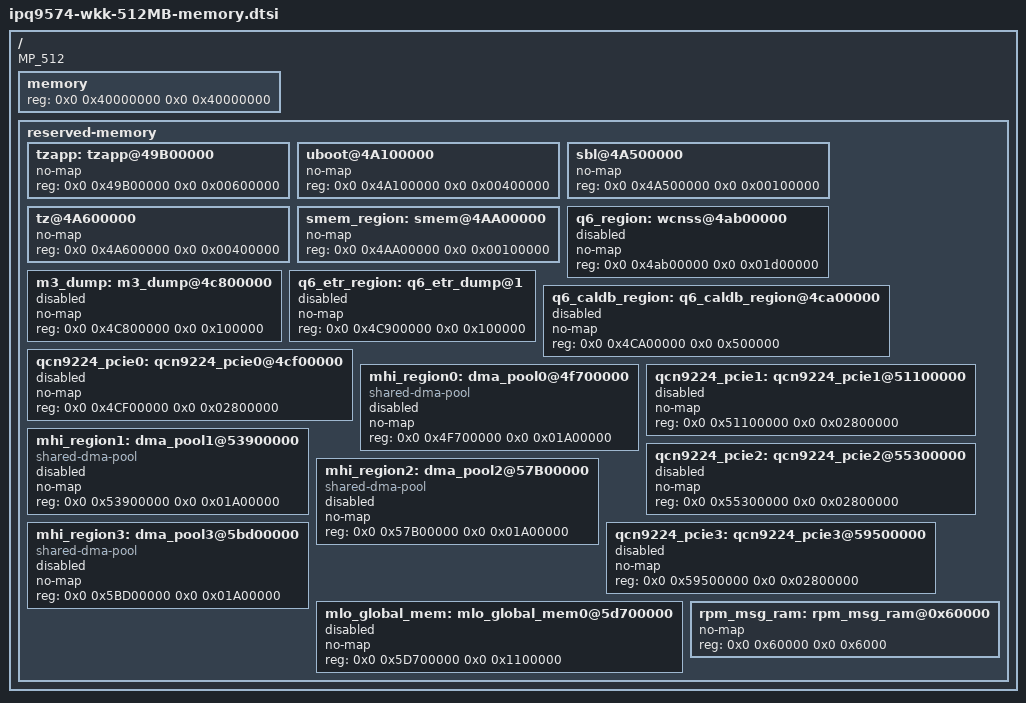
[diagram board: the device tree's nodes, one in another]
// SPDX-License-Identifier: (GPL-2.0+ OR BSD-3-Clause)
/*
 * IPQ9574 Memory device tree source
 *
 * Copyright (c) 2021 The Linux Foundation. All rights reserved.
 * Copyright (c) 2021-2022 Qualcomm Innovation Center, Inc. All rights reserved.
 */

/ {
	MP_512;

	/*		512M Profile for Waikiki
	 * +========+==============+=========================+
	 * |        |              |                         |
	 * | Region | Start Offset |          Size           |
	 * |        |              |                         |
	 * +--------+--------------+-------------------------+
	 * |        |              |                         |
	 * |        |              |                         |
	 * |        |              |                         |
	 * |        |              |                         |
	 * | Linux  |  0x42000000  |         123MB           |
	 * |        |              |                         |
	 * |        |              |                         |
	 * |        |              |                         |
	 * +--------+--------------+-------------------------+
	 * |        |              |                         |
	 * |        |              |                         |
	 * | TZ App |  0x49B00000  |           6MB           |
	 * |        |              |                         |
	 * |        |              |                         |
	 * +--------+--------------+-------------------------+
	 * |        |              |                         |
	 * | uboot  |  0x4A100000  |           4MB           |
	 * |        |              |                         |
	 * +--------+--------------+-------------------------+
	 * |  SBL   |  0x4A500000  |           1MB           |
	 * +--------+--------------+-------------------------+
	 * |        |              |                         |
	 * | TZ+HYP |  0x4A600000  |           4MB           |
	 * |        |              |                         |
	 * +--------+--------------+-------------------------+
	 * |  smem  |  0x4AA00000  |           1MB           |
	 * +--------+--------------+-------------------------+
	 * |        |              |                         |
	 * |        |              |                         |
	 * | WLAN   |              |                         |
	 * |   Q6   |  0x4AB00000  |          29MB           |
	 * |        |              |                         |
	 * |        |              |                         |
	 * +--------+--------------+-------------------------+
	 * | M3 Dump|  0x4C800000  |           1MB           |
	 * +--------+--------------+-------------------------+
	 * | WLAN   |              |                         |
	 * | Q6 ETR |  0x4C900000  |           1MB           |
	 * | Region |              |                         |
	 * +--------+--------------+-------------------------+
	 * | caldb  |  0x4CA00000  |           5MB           |
	 * +--------+--------------+-------------------------+
	 * |        |              |                         |
	 * |  Wkk0  |  0x4CF00000  |          46MB           |
	 * |        |              |                         |
	 * +--------+--------------+-------------------------+
	 * |        |              |                         |
	 * |  MHI0  |  0x4F700000  |          26MB           |
	 * |        |              |                         |
	 * +--------+--------------+-------------------------+
	 * |        |              |                         |
	 * |  Wkk1  |  0x51100000  |          46MB           |
	 * |        |              |                         |
	 * +--------+--------------+-------------------------+
	 * |        |              |                         |
	 * |  MHI1  |  0x53900000  |          26MB           |
	 * |        |              |                         |
	 * +--------+--------------+-------------------------+
	 * |        |              |                         |
	 * |  WKK2  |  0x55300000  |          46MB           |
	 * |        |              |                         |
	 * +--------+--------------+-------------------------+
	 * |        |              |                         |
	 * |  MHI2  |  0x57B00000  |          26MB           |
	 * |        |              |                         |
	 * +--------+--------------+-------------------------+
	 * |        |              |                         |
	 * |  WKK3  |  0x59500000  |          46MB           |
	 * |        |              |                         |
	 * +--------+--------------+-------------------------+
	 * |        |              |                         |
	 * |  MHI3  |  0x5BD00000  |          26MB           |
	 * |        |              |                         |
	 * +--------+--------------+-------------------------+
	 * |        |              |                         |
	 * |  MLO   |  0x5D700000  |          17MB           |
	 * |        |              |                         |
	 * +=================================================+
	 * |                                                 |
	 * |                                                 |
	 * |                                                 |
	 * |            Rest of memory for Linux             |
	 * |                                                 |
	 * |                                                 |
	 * |                                                 |
	 * +=================================================+
	 */

	memory {
		device_type = "memory";
		reg = <0x0 0x40000000 0x0 0x40000000>;
	};

	reserved-memory {
		#address-cells = <2>;
		#size-cells = <2>;
		ranges;

		tzapp:tzapp@49B00000 {  /* TZAPPS */
			no-map;
			reg = <0x0 0x49B00000 0x0 0x00600000>;
		};

		uboot@4A100000 {
			no-map;
			reg = <0x0 0x4A100000 0x0 0x00400000>;
		};

		sbl@4A500000 {
			no-map;
			reg = <0x0 0x4A500000 0x0 0x00100000>;
		};

		tz@4A600000 {
			no-map;
			reg = <0x0 0x4A600000 0x0 0x00400000>;
		};

		smem_region: smem@4AA00000 {
			no-map;
			reg = <0x0 0x4AA00000 0x0 0x00100000>;
		};

		q6_region: wcnss@4ab00000 {
			no-map;
			reg = <0x0 0x4ab00000 0x0 0x01d00000>;
			status = "disabled";
		};

		m3_dump: m3_dump@4c800000 {
			no-map;
			reg = <0x0 0x4C800000 0x0 0x100000>;
			status = "disabled";
		};

		q6_etr_region: q6_etr_dump@1 {
			no-map;
			reg = <0x0 0x4C900000 0x0 0x100000>;
			status = "disabled";
		};

		q6_caldb_region:q6_caldb_region@4ca00000 {
			no-map;
			reg = <0x0 0x4CA00000 0x0 0x500000>;
			status = "disabled";
		};

		qcn9224_pcie0: qcn9224_pcie0@4cf00000 {
			no-map;
			reg = <0x0 0x4CF00000 0x0 0x02800000>;
			status = "disabled";
		};

		mhi_region0: dma_pool0@4f700000 {
			compatible = "shared-dma-pool";
			no-map;
			reg = <0x0 0x4F700000 0x0 0x01A00000>;
			status = "disabled";
		};

		qcn9224_pcie1: qcn9224_pcie1@51100000 {
			no-map;
			reg = <0x0 0x51100000 0x0 0x02800000>;
			status = "disabled";
		};

		mhi_region1: dma_pool1@53900000 {
			compatible = "shared-dma-pool";
			no-map;
			reg = <0x0 0x53900000 0x0 0x01A00000>;
			status = "disabled";
		};

		qcn9224_pcie2: qcn9224_pcie2@55300000 {
			no-map;
			reg = <0x0 0x55300000 0x0 0x02800000>;
			status = "disabled";
		};

		mhi_region2: dma_pool2@57B00000 {
			compatible = "shared-dma-pool";
			no-map;
			reg = <0x0 0x57B00000 0x0 0x01A00000>;
			status = "disabled";
		};

		qcn9224_pcie3: qcn9224_pcie3@59500000 {
			no-map;
			reg = <0x0 0x59500000 0x0 0x02800000>;
			status = "disabled";
		};

		mhi_region3: dma_pool3@5bd00000 {
			compatible = "shared-dma-pool";
			no-map;
			reg = <0x0 0x5BD00000 0x0 0x01A00000>;
			status = "disabled";
		};

		mlo_global_mem: mlo_global_mem0@5d700000 {
			no-map;
			reg = <0x0 0x5D700000 0x0 0x1100000>;
			status = "disabled";
		};

		rpm_msg_ram: rpm_msg_ram@0x60000 {
			no-map;
			reg = <0x0 0x60000 0x0 0x6000>;
		};
	};
};
